VERSION ""

NS_ :

BS_:

BU_:
VAL_TABLE_ J1939_BaudRate 255 "unchanged" 2 "500K" 1 "250K" 0 "unchanged" ;
VAL_TABLE_ Encoder_PresetActive 1 "Set Preset" 0 "Ignore Preset Value" ;
VAL_TABLE_ CAN_Termination 2 "unchanged" 1 "ON" 0 "OFF" ;

BO_ 3221225472 VECTOR__INDEPENDENT_SIG_MSG: 0 Vector__XXX
 SG_ NetworkMessageControlByte : 0|8@1+ (1,0) [0|255] "" Vector__XXX
 SG_ EncoderSetupF_SensorCycleTimeBAM : 0|32@1+ (1,0) [0|0] "" Vector__XXX

BO_ 256 Invoke_BootLoader: 8 Vector__XXX

BO_ 2364481537 EncoderSetup: 21 Vector__XXX
 SG_ EncoderSetupI_BaudRate : 160|8@1+ (1,0) [0|255] "" Vector__XXX
 SG_ EncoderSetupH_SensorPresetEnable : 152|8@1+ (1,0) [0|0] "" Vector__XXX
 SG_ EncoderSetupG_SensorPresetValue : 120|32@1+ (1,0) [0|0] "" Vector__XXX
 SG_ EncoderSetupE_CANBusTermination : 112|8@1+ (1,0) [0|0] "" Vector__XXX
 SG_ EncoderSetupD_SensorCycleTime : 80|32@1+ (1,0) [0|0] "" Vector__XXX
 SG_ EncoderSetupC_TMR : 48|32@1+ (1,0) [0|0] "" Vector__XXX
 SG_ EncoderSetupB_MUR : 16|32@1+ (1,0) [0|0] "" Vector__XXX
 SG_ EncoderSetupA_OperatingParameter : 0|16@1+ (1,0) [0|0] "" Vector__XXX

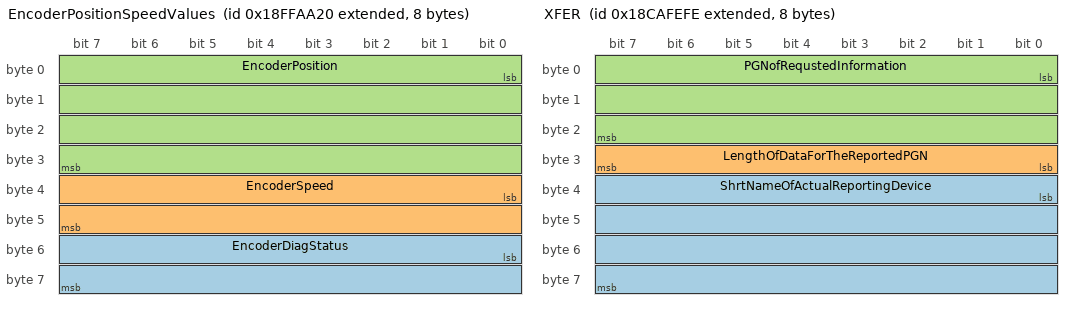
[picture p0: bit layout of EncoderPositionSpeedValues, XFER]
BO_ 2566892064 EncoderPositionSpeedValues: 8 Vector__XXX
 SG_ EncoderDiagStatus : 48|16@1+ (1,0) [0|0] "" Vector__XXX
 SG_ EncoderSpeed : 32|16@1- (1,0) [0|0] "RPM" Vector__XXX
 SG_ EncoderPosition : 0|32@1+ (0.00001,0) [0|0] "" Vector__XXX

BO_ 2566786302 WSMEM: 8 Vector__XXX
 SG_ VehicleSystem5 m5 : 49|7@1+ (1,0) [0|127] "" Vector__XXX
 SG_ VehicleSystem4 m4 : 49|7@1+ (1,0) [0|127] "" Vector__XXX
 SG_ VehicleSystem3 m3 : 49|7@1+ (1,0) [0|127] "" Vector__XXX
 SG_ VehicleSystem2 m2 : 49|7@1+ (1,0) [0|127] "" Vector__XXX
 SG_ VehicleSystem1 m1 : 49|7@1+ (1,0) [0|127] "" Vector__XXX
 SG_ ArbitraryAddressCapable : 63|1@1+ (1,0) [0|1] "" Vector__XXX
 SG_ IndustryGroup M : 60|3@1+ (1,0) [0|7] "" Vector__XXX
 SG_ VehicleSystemInstance : 56|4@1+ (1,0) [0|15] "" Vector__XXX
 SG_ VehicleSystem m0 : 49|7@1+ (1,0) [0|127] "" Vector__XXX
 SG_ ECUInstance : 32|3@1+ (1,0) [0|7] "" Vector__XXX
 SG_ FunctionInstance : 35|5@1+ (1,0) [0|31] "" Vector__XXX
 SG_ Function : 40|8@1+ (1,0) [0|255] "" Vector__XXX
 SG_ ManufacturerCode : 21|11@1+ (1,0) [0|2047] "" Vector__XXX
 SG_ IdentityNumber : 0|21@1+ (1,0) [0|2097152] "" Vector__XXX

BO_ 2566786558 WSMSTR: 8 Vector__XXX
 SG_ NumberOfMembers : 0|8@1+ (1,0) [0|0] "" Vector__XXX

BO_ 2566838526 CA: 9 Vector__XXX
 SG_ AddressAssignment : 64|8@1+ (1,0) [0|255] "" Vector__XXX
 SG_ ArbitraryAddressCapable : 63|1@1+ (1,0) [0|1] "" Vector__XXX
 SG_ IndustryGroup M : 60|3@1+ (1,0) [0|7] "" Vector__XXX
 SG_ VehicleSystemInstance : 56|4@1+ (1,0) [0|15] "" Vector__XXX
 SG_ Function : 40|8@1+ (1,0) [0|255] "" Vector__XXX
 SG_ VehicleSystem m0 : 49|7@1+ (1,0) [0|127] "" Vector__XXX
 SG_ FunctionInstance : 35|5@1+ (1,0) [0|31] "" Vector__XXX
 SG_ ECUInstance : 32|3@1+ (1,0) [0|7] "" Vector__XXX
 SG_ ManufacturerCode : 21|11@1+ (1,0) [0|2047] "" Vector__XXX
 SG_ IdentityNumber : 0|21@1+ (1,0) [0|2097152] "" Vector__XXX
 SG_ VehicleSystem5 m5 : 49|7@1+ (1,0) [0|127] "" Vector__XXX
 SG_ VehicleSystem4 m4 : 49|7@1+ (1,0) [0|127] "" Vector__XXX
 SG_ VehicleSystem3 m3 : 49|7@1+ (1,0) [0|127] "" Vector__XXX
 SG_ VehicleSystem2 m2 : 49|7@1+ (1,0) [0|127] "" Vector__XXX
 SG_ VehicleSystem1 m1 : 49|7@1+ (1,0) [0|127] "" Vector__XXX

BO_ 2565799678 AC: 8 Vector__XXX
 SG_ ArbitraryAddressCapable : 63|1@1+ (1,0) [0|1] "" Vector__XXX
 SG_ IndustryGroup M : 60|3@1+ (1,0) [0|7] "" Vector__XXX
 SG_ VehicleSystemInstance : 56|4@1+ (1,0) [0|15] "" Vector__XXX
 SG_ Function : 40|8@1+ (1,0) [0|255] "" Vector__XXX
 SG_ FunctionInstance : 35|5@1+ (1,0) [0|31] "" Vector__XXX
 SG_ ECUInstance : 32|3@1+ (1,0) [0|7] "" Vector__XXX
 SG_ ManufacturerCode : 21|11@1+ (1,0) [0|2047] "" Vector__XXX
 SG_ IdentityNumber : 0|21@1+ (1,0) [0|2097152] "" Vector__XXX
 SG_ VehicleSystem m0 : 49|7@1+ (1,0) [0|127] "" Vector__XXX
 SG_ VehicleSystem5 m5 : 49|7@1+ (1,0) [0|127] "" Vector__XXX
 SG_ VehicleSystem4 m4 : 49|7@1+ (1,0) [0|127] "" Vector__XXX
 SG_ VehicleSystem3 m3 : 49|7@1+ (1,0) [0|127] "" Vector__XXX
 SG_ VehicleSystem2 m2 : 49|7@1+ (1,0) [0|127] "" Vector__XXX
 SG_ VehicleSystem1 m1 : 49|7@1+ (1,0) [0|127] "" Vector__XXX

BO_ 2563440382 XFER: 8 Vector__XXX
 SG_ ShrtNameOfActualReportingDevice : 32|32@1+ (1,0) [0|0] "" Vector__XXX
 SG_ LengthOfDataForTheReportedPGN : 24|8@1+ (1,0) [0|255] "" Vector__XXX
 SG_ PGNofRequstedInformation : 0|24@1+ (1,0) [0|16777215] "" Vector__XXX

BO_ 2565603070 TPDT: 8 Vector__XXX
 SG_ SequenceNumber : 0|8@1+ (1,0) [0|255] "" Vector__XXX

BO_ 2565668606 TPCMxx: 8 Vector__XXX
 SG_ TotalNumberOfPacketsEoMA m19 : 24|8@1+ (1,0) [0|255] "" Vector__XXX
 SG_ TotalMessageSizeEoMA m19 : 8|16@1+ (1,0) [0|64255] "" Vector__XXX
 SG_ TotalMessageSizeBAM m32 : 8|16@1+ (1,0) [0|64255] "" Vector__XXX
 SG_ TotalNumberOfPacketsBAM m32 : 24|8@1+ (1,0) [0|255] "" Vector__XXX
 SG_ ConnectionAbortReason m255 : 8|8@1+ (1,0) [0|255] "" Vector__XXX
 SG_ NextPacketNumberToBeSent m17 : 16|8@1+ (1,0) [0|255] "" Vector__XXX
 SG_ NumberOfPacketsThatCanBeSent m17 : 8|8@1+ (1,0) [0|255] "" Vector__XXX
 SG_ PGNumber : 40|24@1+ (1,0) [0|16777200] "" Vector__XXX
 SG_ MaximumNumberOfPackets m16 : 32|8@1+ (1,0) [0|255] "" Vector__XXX
 SG_ TotalNumberOfPackets m16 : 24|8@1+ (1,0) [0|255] "" Vector__XXX
 SG_ TotalMessageSize m16 : 8|16@1+ (1,0) [0|64255] "" Vector__XXX
 SG_ ControlByte M : 0|8@1+ (1,0) [0|255] "" Vector__XXX

BO_ 2563374846 RQST2: 8 Vector__XXX
 SG_ ParameterGroupNumber : 0|24@1+ (1,0) [0|16777215] "" Vector__XXX
 SG_ UseTransferMode : 24|2@1+ (1,0) [0|3] "" Vector__XXX

BO_ 2565537534 RQST: 3 Vector__XXX
 SG_ ParameterGroupNumber : 0|24@1+ (1,0) [0|16777215] "" Vector__XXX

BO_ 2565406462 ACKM: 8 Vector__XXX
 SG_ AddressBusy m3 : 32|8@1+ (1,0) [0|255] "" Vector__XXX
 SG_ ControlByte M : 0|8@1+ (1,0) [0|255] "" Vector__XXX
 SG_ ParameterGroupNumber : 40|24@1+ (1,0) [0|16777215] "" Vector__XXX
 SG_ GroupFunctionValue : 8|8@1+ (1,0) [0|255] "" Vector__XXX
 SG_ AddressAccessDenied m2 : 32|8@1+ (1,0) [0|255] "" Vector__XXX
 SG_ AddressNegativeAcknowledgement m1 : 32|8@1+ (1,0) [0|255] "" Vector__XXX
 SG_ AddressAcknowledged m0 : 32|8@1+ (1,0) [0|255] "" Vector__XXX
